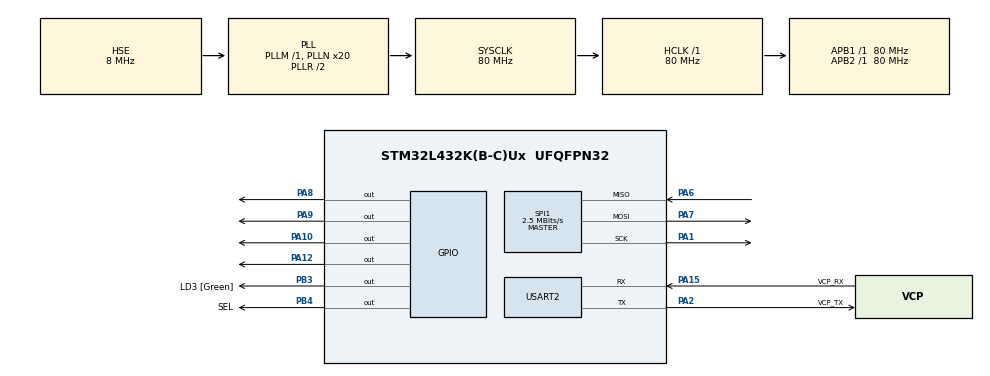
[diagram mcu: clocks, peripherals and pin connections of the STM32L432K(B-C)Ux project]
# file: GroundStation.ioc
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Mcu.Family=STM32L4
Mcu.Name=STM32L432K(B-C)Ux
Mcu.Package=UFQFPN32
NVIC.PriorityGroup=NVIC_PRIORITYGROUP_4
NVIC.USART2_IRQn=true\:1\:0\:true\:false\:true\:true\:true
PA0.GPIO_Label=MCO [High speed clock in]
PA0.Mode=HSE-External-Clock-Source-for-LittleOrca
PA0.Signal=RCC_CK_IN
PA1.Mode=Full_Duplex_Master
PA1.Signal=SPI1_SCK
PA10.Signal=GPIO_Output
PA12.PinState=GPIO_PIN_SET
PA12.Signal=GPIO_Output
PA13\ (JTMS-SWDIO).GPIO_Label=SWDIO
PA13\ (JTMS-SWDIO).Mode=Serial_Wire
PA13\ (JTMS-SWDIO).Signal=SYS_JTMS-SWDIO
PA14\ (JTCK-SWCLK).GPIO_Label=SWCLK
PA14\ (JTCK-SWCLK).Mode=Serial_Wire
PA14\ (JTCK-SWCLK).Signal=SYS_JTCK-SWCLK
PA15\ (JTDI).GPIO_Label=VCP_RX
PA15\ (JTDI).Mode=Asynchronous
PA15\ (JTDI).Signal=USART2_RX
PA2.GPIO_Label=VCP_TX
PA2.Mode=Asynchronous
PA2.Signal=USART2_TX
PA6.Mode=Full_Duplex_Master
PA6.Signal=SPI1_MISO
PA7.Mode=Full_Duplex_Master
PA7.Signal=SPI1_MOSI
PA8.PinState=GPIO_PIN_SET
PA8.Signal=GPIO_Output
PA9.Signal=GPIO_Output
PB3\ (JTDO-TRACESWO).GPIO_Label=LD3 [Green]
PB3\ (JTDO-TRACESWO).GPIO_Speed=GPIO_SPEED_FREQ_VERY_HIGH
PB3\ (JTDO-TRACESWO).Signal=GPIO_Output
PB4\ (NJTRST).GPIO_Label=SEL
PB4\ (NJTRST).GPIO_Speed=GPIO_SPEED_FREQ_MEDIUM
PB4\ (NJTRST).PinState=GPIO_PIN_SET
PB4\ (NJTRST).Signal=GPIO_Output
PC14-OSC32_IN\ (PC14).Mode=LSE-External-Oscillator
PC14-OSC32_IN\ (PC14).Signal=RCC_OSC32_IN
PC15-OSC32_OUT\ (PC15).Mode=LSE-External-Oscillator
PC15-OSC32_OUT\ (PC15).Signal=RCC_OSC32_OUT
ProjectManager.HeapSize=0x600
ProjectManager.StackSize=0x600
ProjectManager.TargetToolchain=SW4STM32
RCC.ADCFreq_Value=32000000
RCC.AHBFreq_Value=80000000
RCC.APB1Freq_Value=80000000
RCC.APB1TimFreq_Value=80000000
RCC.APB2Freq_Value=80000000
RCC.APB2TimFreq_Value=80000000
RCC.CortexFreq_Value=80000000
RCC.HCLKFreq_Value=80000000
RCC.HSE_VALUE=8000000
RCC.HSI16_VALUE=16000000
RCC.HSI48_VALUE=48000000
RCC.HSI_VALUE=16000000
RCC.MSI_VALUE=4000000
RCC.PLLMUL=RCC_PLLMUL_4
RCC.PLLN=20
RCC.PLLSourceVirtual=RCC_PLLSOURCE_HSE
RCC.SYSCLKFreq_VALUE=80000000
RCC.SYSCLKSource=RCC_SYSCLKSOURCE_PLLCLK
RCC.USBFreq_Value=32000000
RCC.VCOOutputFreq_Value=160000000
SPI1.BaudRatePrescaler=SPI_BAUDRATEPRESCALER_32
SPI1.CalculateBaudRate=2.5 MBits/s
SPI1.DataSize=SPI_DATASIZE_8BIT
SPI1.Direction=SPI_DIRECTION_2LINES
SPI1.Mode=SPI_MODE_MASTER
SPI1.VirtualType=VM_MASTER
USART2.DMADisableonRxErrorParam=ADVFEATURE_DMA_DISABLEONRXERROR
USART2.OverrunDisableParam=ADVFEATURE_OVERRUN_DISABLE
USART2.VirtualMode-Asynchronous=VM_ASYNC
board=NUCLEO-L432KC

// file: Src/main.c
/* USER CODE BEGIN Header */
/**
  ******************************************************************************
  * @file           : main.c
  * @brief          : Main program body
  ******************************************************************************
  * @attention
  *
  * <h2><center>&copy; Copyright (c) 2019 STMicroelectronics.
  * All rights reserved.</center></h2>
  *
  * This software component is licensed by ST under BSD 3-Clause license,
  * the "License"; You may not use this file except in compliance with the
  * License. You may obtain a copy of the License at:
  *                        opensource.org/licenses/BSD-3-Clause
  *
  ******************************************************************************
  */
/* USER CODE END Header */

#include "main.h"

/* USER CODE BEGIN Includes */
#include <mockup.h>
/* USER CODE END Includes */

SPI_HandleTypeDef hspi1;

void SystemClock_Config(void);
static void MX_GPIO_Init(void);
static void MX_SPI1_Init(void);
static void MX_USART2_UART_Init(void);

int main(void)
{

  /* MCU Configuration--------------------------------------------------------*/

  /* Reset of all peripherals, Initializes the Flash interface and the Systick. */
  HAL_Init();

  /* Configure the system clock */
  SystemClock_Config();

  /* Initialize all configured peripherals */
  MX_GPIO_Init();
  MX_SPI1_Init();
  MX_USART2_UART_Init();
  /* USER CODE BEGIN 2 */
  LL_USART_EnableIT_RXNE(USART2);
  /* USER CODE END 2 */

  /* Infinite loop */
  /* USER CODE BEGIN WHILE */
  while (1)
  {
      main_cpp();
    /* USER CODE END WHILE */

  }
}

void SystemClock_Config(void)
{
  RCC_OscInitTypeDef RCC_OscInitStruct = {0};
  RCC_ClkInitTypeDef RCC_ClkInitStruct = {0};
  RCC_PeriphCLKInitTypeDef PeriphClkInit = {0};

  /** Initializes the CPU, AHB and APB busses clocks
  */
  RCC_OscInitStruct.OscillatorType = RCC_OSCILLATORTYPE_HSE;
  RCC_OscInitStruct.HSEState = RCC_HSE_BYPASS;
  RCC_OscInitStruct.PLL.PLLState = RCC_PLL_ON;
  RCC_OscInitStruct.PLL.PLLSource = RCC_PLLSOURCE_HSE;
  RCC_OscInitStruct.PLL.PLLM = 1;
  RCC_OscInitStruct.PLL.PLLN = 20;
  RCC_OscInitStruct.PLL.PLLP = RCC_PLLP_DIV7;
  RCC_OscInitStruct.PLL.PLLQ = RCC_PLLQ_DIV2;
  RCC_OscInitStruct.PLL.PLLR = RCC_PLLR_DIV2;
  if (HAL_RCC_OscConfig(&RCC_OscInitStruct) != HAL_OK)
  {
    Error_Handler();
  }
  /** Initializes the CPU, AHB and APB busses clocks
  */
  RCC_ClkInitStruct.ClockType = RCC_CLOCKTYPE_HCLK|RCC_CLOCKTYPE_SYSCLK
                              |RCC_CLOCKTYPE_PCLK1|RCC_CLOCKTYPE_PCLK2;
  RCC_ClkInitStruct.SYSCLKSource = RCC_SYSCLKSOURCE_PLLCLK;
  RCC_ClkInitStruct.AHBCLKDivider = RCC_SYSCLK_DIV1;
  RCC_ClkInitStruct.APB1CLKDivider = RCC_HCLK_DIV1;
  RCC_ClkInitStruct.APB2CLKDivider = RCC_HCLK_DIV1;

  if (HAL_RCC_ClockConfig(&RCC_ClkInitStruct, FLASH_LATENCY_4) != HAL_OK)
  {
    Error_Handler();
  }
  PeriphClkInit.PeriphClockSelection = RCC_PERIPHCLK_USART2;
  PeriphClkInit.Usart2ClockSelection = RCC_USART2CLKSOURCE_PCLK1;
  if (HAL_RCCEx_PeriphCLKConfig(&PeriphClkInit) != HAL_OK)
  {
    Error_Handler();
  }
  /** Configure the main internal regulator output voltage
  */
  if (HAL_PWREx_ControlVoltageScaling(PWR_REGULATOR_VOLTAGE_SCALE1) != HAL_OK)
  {
    Error_Handler();
  }
}

static void MX_SPI1_Init(void)
{

  /* SPI1 parameter configuration*/
  hspi1.Instance = SPI1;
  hspi1.Init.Mode = SPI_MODE_MASTER;
  hspi1.Init.Direction = SPI_DIRECTION_2LINES;
  hspi1.Init.DataSize = SPI_DATASIZE_8BIT;
  hspi1.Init.CLKPolarity = SPI_POLARITY_LOW;
  hspi1.Init.CLKPhase = SPI_PHASE_1EDGE;
  hspi1.Init.NSS = SPI_NSS_SOFT;
  hspi1.Init.BaudRatePrescaler = SPI_BAUDRATEPRESCALER_32;
  hspi1.Init.FirstBit = SPI_FIRSTBIT_MSB;
  hspi1.Init.TIMode = SPI_TIMODE_DISABLE;
  hspi1.Init.CRCCalculation = SPI_CRCCALCULATION_DISABLE;
  hspi1.Init.CRCPolynomial = 7;
  hspi1.Init.CRCLength = SPI_CRC_LENGTH_DATASIZE;
  hspi1.Init.NSSPMode = SPI_NSS_PULSE_ENABLE;
  if (HAL_SPI_Init(&hspi1) != HAL_OK)
  {
    Error_Handler();
  }

}

static void MX_USART2_UART_Init(void)
{

  LL_USART_InitTypeDef USART_InitStruct = {0};

  LL_GPIO_InitTypeDef GPIO_InitStruct = {0};

  /* Peripheral clock enable */
  LL_APB1_GRP1_EnableClock(LL_APB1_GRP1_PERIPH_USART2);

  LL_AHB2_GRP1_EnableClock(LL_AHB2_GRP1_PERIPH_GPIOA);
  /**USART2 GPIO Configuration
  PA2   ------> USART2_TX
  PA15 (JTDI)   ------> USART2_RX
  */
  GPIO_InitStruct.Pin = LL_GPIO_PIN_2;
  GPIO_InitStruct.Mode = LL_GPIO_MODE_ALTERNATE;
  GPIO_InitStruct.Speed = LL_GPIO_SPEED_FREQ_VERY_HIGH;
  GPIO_InitStruct.OutputType = LL_GPIO_OUTPUT_PUSHPULL;
  GPIO_InitStruct.Pull = LL_GPIO_PULL_NO;
  GPIO_InitStruct.Alternate = LL_GPIO_AF_7;
  LL_GPIO_Init(GPIOA, &GPIO_InitStruct);

  GPIO_InitStruct.Pin = LL_GPIO_PIN_15;
  GPIO_InitStruct.Mode = LL_GPIO_MODE_ALTERNATE;
  GPIO_InitStruct.Speed = LL_GPIO_SPEED_FREQ_VERY_HIGH;
  GPIO_InitStruct.OutputType = LL_GPIO_OUTPUT_PUSHPULL;
  GPIO_InitStruct.Pull = LL_GPIO_PULL_NO;
  GPIO_InitStruct.Alternate = LL_GPIO_AF_3;
  LL_GPIO_Init(GPIOA, &GPIO_InitStruct);

  /* USART2 interrupt Init */
  NVIC_SetPriority(USART2_IRQn, NVIC_EncodePriority(NVIC_GetPriorityGrouping(),1, 0));
  NVIC_EnableIRQ(USART2_IRQn);

  USART_InitStruct.BaudRate = 115200;
  USART_InitStruct.DataWidth = LL_USART_DATAWIDTH_8B;
  USART_InitStruct.StopBits = LL_USART_STOPBITS_1;
  USART_InitStruct.Parity = LL_USART_PARITY_NONE;
  USART_InitStruct.TransferDirection = LL_USART_DIRECTION_TX_RX;
  USART_InitStruct.HardwareFlowControl = LL_USART_HWCONTROL_NONE;
  USART_InitStruct.OverSampling = LL_USART_OVERSAMPLING_16;
  LL_USART_Init(USART2, &USART_InitStruct);
  LL_USART_DisableOverrunDetect(USART2);
  LL_USART_DisableDMADeactOnRxErr(USART2);
  LL_USART_ConfigAsyncMode(USART2);
  LL_USART_Enable(USART2);

}

static void MX_GPIO_Init(void)
{
  GPIO_InitTypeDef GPIO_InitStruct = {0};

  /* GPIO Ports Clock Enable */
  __HAL_RCC_GPIOC_CLK_ENABLE();
  __HAL_RCC_GPIOA_CLK_ENABLE();
  __HAL_RCC_GPIOB_CLK_ENABLE();

  /*Configure GPIO pin Output Level */
  HAL_GPIO_WritePin(GPIOA, GPIO_PIN_8|GPIO_PIN_12, GPIO_PIN_SET);

  /*Configure GPIO pin Output Level */
  HAL_GPIO_WritePin(GPIOA, GPIO_PIN_9|GPIO_PIN_10, GPIO_PIN_RESET);

  /*Configure GPIO pin Output Level */
  HAL_GPIO_WritePin(LD3_GPIO_Port, LD3_Pin, GPIO_PIN_RESET);

  /*Configure GPIO pin Output Level */
  HAL_GPIO_WritePin(SEL_GPIO_Port, SEL_Pin, GPIO_PIN_SET);

  /*Configure GPIO pins : PA8 PA9 PA10 PA12 */
  GPIO_InitStruct.Pin = GPIO_PIN_8|GPIO_PIN_9|GPIO_PIN_10|GPIO_PIN_12;
  GPIO_InitStruct.Mode = GPIO_MODE_OUTPUT_PP;
  GPIO_InitStruct.Pull = GPIO_NOPULL;
  GPIO_InitStruct.Speed = GPIO_SPEED_FREQ_LOW;
  HAL_GPIO_Init(GPIOA, &GPIO_InitStruct);

  /*Configure GPIO pin : LD3_Pin */
  GPIO_InitStruct.Pin = LD3_Pin;
  GPIO_InitStruct.Mode = GPIO_MODE_OUTPUT_PP;
  GPIO_InitStruct.Pull = GPIO_NOPULL;
  GPIO_InitStruct.Speed = GPIO_SPEED_FREQ_VERY_HIGH;
  HAL_GPIO_Init(LD3_GPIO_Port, &GPIO_InitStruct);

  /*Configure GPIO pin : SEL_Pin */
  GPIO_InitStruct.Pin = SEL_Pin;
  GPIO_InitStruct.Mode = GPIO_MODE_OUTPUT_PP;
  GPIO_InitStruct.Pull = GPIO_NOPULL;
  GPIO_InitStruct.Speed = GPIO_SPEED_FREQ_MEDIUM;
  HAL_GPIO_Init(SEL_GPIO_Port, &GPIO_InitStruct);

}

void Error_Handler(void)
{
}

/************************ (C) COPYRIGHT STMicroelectronics *****END OF FILE****/
